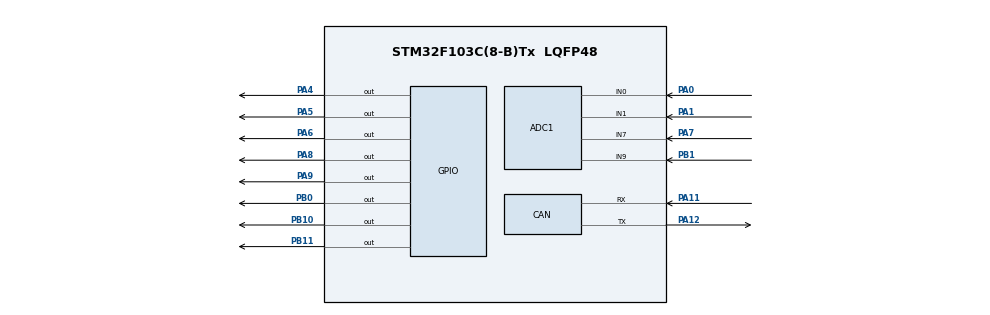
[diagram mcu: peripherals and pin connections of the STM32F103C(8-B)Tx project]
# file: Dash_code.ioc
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ADC1.Channel-0\#ChannelRegularConversion=ADC_CHANNEL_1
ADC1.NbrOfConversionFlag=1
ADC1.Rank-0\#ChannelRegularConversion=1
ADC1.SamplingTime-0\#ChannelRegularConversion=ADC_SAMPLETIME_1CYCLE_5
ADC1.master=1
CAN.CalculateTimeBit=6000
CAN.CalculateTimeQuantum=2000.0
Mcu.Family=STM32F1
Mcu.Name=STM32F103C(8-B)Tx
Mcu.Package=LQFP48
NVIC.PriorityGroup=NVIC_PRIORITYGROUP_4
PA0-WKUP.Signal=ADCx_IN0
PA1.Signal=ADCx_IN1
PA11.Mode=Master
PA11.Signal=CAN_RX
PA12.Mode=Master
PA12.Signal=CAN_TX
PA4.Signal=GPIO_Output
PA5.Signal=GPIO_Output
PA6.Signal=GPIO_Output
PA7.Signal=ADCx_IN7
PA8.Signal=GPIO_Output
PA9.Signal=GPIO_Output
PB0.Signal=GPIO_Output
PB1.Signal=ADCx_IN9
PB10.Signal=GPIO_Output
PB11.Signal=GPIO_Output
ProjectManager.HeapSize=0x200
ProjectManager.StackSize=0x400
ProjectManager.TargetToolchain=Makefile
RCC.APB1Freq_Value=8000000
RCC.APB2Freq_Value=8000000
SH.ADCx_IN0.0=ADC1_IN0,IN0
SH.ADCx_IN1.0=ADC1_IN1,IN1
SH.ADCx_IN7.0=ADC1_IN7,IN7
SH.ADCx_IN9.0=ADC1_IN9,IN9
VP_SYS_VS_ND.Mode=No_Debug
board=custom

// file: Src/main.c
/* USER CODE BEGIN Header */
/**
  ******************************************************************************
  * @file           : main.c
  * @brief          : Main program body
  ******************************************************************************
  ** This notice applies to any and all portions of this file
  * that are not between comment pairs USER CODE BEGIN and
  * USER CODE END. Other portions of this file, whether
  * inserted by the user or by software development tools
  * are owned by their respective copyright owners.
  *
  * COPYRIGHT(c) 2019 STMicroelectronics
  *
  * Redistribution and use in source and binary forms, with or without modification,
  * are permitted provided that the following conditions are met:
  *   1. Redistributions of source code must retain the above copyright notice,
  *      this list of conditions and the following disclaimer.
  *   2. Redistributions in binary form must reproduce the above copyright notice,
  *      this list of conditions and the following disclaimer in the documentation
  *      and/or other materials provided with the distribution.
  *   3. Neither the name of STMicroelectronics nor the names of its contributors
  *      may be used to endorse or promote products derived from this software
  *      without specific prior written permission.
  *
  * THIS SOFTWARE IS PROVIDED BY THE COPYRIGHT HOLDERS AND CONTRIBUTORS "AS IS"
  * AND ANY EXPRESS OR IMPLIED WARRANTIES, INCLUDING, BUT NOT LIMITED TO, THE
  * IMPLIED WARRANTIES OF MERCHANTABILITY AND FITNESS FOR A PARTICULAR PURPOSE ARE
  * DISCLAIMED. IN NO EVENT SHALL THE COPYRIGHT HOLDER OR CONTRIBUTORS BE LIABLE
  * FOR ANY DIRECT, INDIRECT, INCIDENTAL, SPECIAL, EXEMPLARY, OR CONSEQUENTIAL
  * DAMAGES (INCLUDING, BUT NOT LIMITED TO, PROCUREMENT OF SUBSTITUTE GOODS OR
  * SERVICES; LOSS OF USE, DATA, OR PROFITS; OR BUSINESS INTERRUPTION) HOWEVER
  * CAUSED AND ON ANY THEORY OF LIABILITY, WHETHER IN CONTRACT, STRICT LIABILITY,
  * OR TORT (INCLUDING NEGLIGENCE OR OTHERWISE) ARISING IN ANY WAY OUT OF THE USE
  * OF THIS SOFTWARE, EVEN IF ADVISED OF THE POSSIBILITY OF SUCH DAMAGE.
  *
  ******************************************************************************
  */
/* USER CODE END Header */

#include "main.h"

/* USER CODE BEGIN Includes */
//#include "stm32f0xx_hal.h"
/* USER CODE END Includes */

ADC_HandleTypeDef hadc1;
ADC_ChannelConfTypeDef sConfig;

CAN_HandleTypeDef hcan;

/* USER CODE BEGIN PV */
uint16_t adc0,adc1,adc7,adc9;

/* USER CODE END PV */

void SystemClock_Config(void);
static void MX_GPIO_Init(void);
static void MX_CAN_Init(void);
static void MX_ADC1_Init(void);
uint16_t readADC_Val(void);

int main(void)
{

  /* MCU Configuration--------------------------------------------------------*/

  /* Reset of all peripherals, Initializes the Flash interface and the Systick. */
  HAL_Init();

  /* Configure the system clock */
  SystemClock_Config();

  /* Initialize all configured peripherals */
  MX_GPIO_Init();
  MX_CAN_Init();
  MX_ADC1_Init();
  /* USER CODE BEGIN 2 */
  //ConfigureADC();
  HAL_ADC_Start_IT(&hadc1);
  sConfig.Channel = ADC_CHANNEL_0;
  adc0 = readADC_Val();
  sConfig.Channel = ADC_CHANNEL_1;
  adc1 = readADC_Val();
  sConfig.Channel = ADC_CHANNEL_7;
  adc7 = readADC_Val();
  sConfig.Channel = ADC_CHANNEL_9;
  adc9 = readADC_Val();
  /* USER CODE END 2 */

  /* Infinite loop */
  while (1)
  {

  }
}

uint16_t readADC_Val(void)
{
	//chConfig.Channel = channel; //configure channel to be read
	sConfig.Rank =  ADC_REGULAR_RANK_1;
	sConfig.SamplingTime = ADC_SAMPLETIME_1CYCLE_5;
	HAL_ADC_ConfigChannel(&hadc1, &sConfig);

	HAL_ADC_Start_IT(&hadc1);
	HAL_ADCEx_Calibration_Start(&hadc1);

	uint32_t value = HAL_ADC_GetValue(&hadc1);

	HAL_ADC_Stop_IT(&hadc1);
	sConfig.Rank = ADC_REGULAR_RANK_1;
	HAL_ADC_ConfigChannel(&hadc1,&sConfig);

	uint16_t value2 = (uint16_t)value;
	//sprintf(TextBuffer,"%u\n",value2);
	return value2;
}

void SystemClock_Config(void)
{
  RCC_OscInitTypeDef RCC_OscInitStruct = {0};
  RCC_ClkInitTypeDef RCC_ClkInitStruct = {0};
  RCC_PeriphCLKInitTypeDef PeriphClkInit = {0};

  /**Initializes the CPU, AHB and APB busses clocks
  */
  RCC_OscInitStruct.OscillatorType = RCC_OSCILLATORTYPE_HSI;
  RCC_OscInitStruct.HSIState = RCC_HSI_ON;
  RCC_OscInitStruct.HSICalibrationValue = RCC_HSICALIBRATION_DEFAULT;
  RCC_OscInitStruct.PLL.PLLState = RCC_PLL_NONE;
  if (HAL_RCC_OscConfig(&RCC_OscInitStruct) != HAL_OK)
  {
    Error_Handler();
  }
  /**Initializes the CPU, AHB and APB busses clocks
  */
  RCC_ClkInitStruct.ClockType = RCC_CLOCKTYPE_HCLK|RCC_CLOCKTYPE_SYSCLK
                              |RCC_CLOCKTYPE_PCLK1|RCC_CLOCKTYPE_PCLK2;
  RCC_ClkInitStruct.SYSCLKSource = RCC_SYSCLKSOURCE_HSI;
  RCC_ClkInitStruct.AHBCLKDivider = RCC_SYSCLK_DIV1;
  RCC_ClkInitStruct.APB1CLKDivider = RCC_HCLK_DIV1;
  RCC_ClkInitStruct.APB2CLKDivider = RCC_HCLK_DIV1;

  if (HAL_RCC_ClockConfig(&RCC_ClkInitStruct, FLASH_LATENCY_0) != HAL_OK)
  {
    Error_Handler();
  }
  PeriphClkInit.PeriphClockSelection = RCC_PERIPHCLK_ADC;
  PeriphClkInit.AdcClockSelection = RCC_ADCPCLK2_DIV2;
  if (HAL_RCCEx_PeriphCLKConfig(&PeriphClkInit) != HAL_OK)
  {
    Error_Handler();
  }
}

static void MX_ADC1_Init(void)
{

  //ADC_ChannelConfTypeDef sConfig = {0};

  /**Common config
  */
  hadc1.Instance = ADC1;
  hadc1.Init.ScanConvMode = ADC_SCAN_DISABLE;
  hadc1.Init.ContinuousConvMode = DISABLE;
  hadc1.Init.DiscontinuousConvMode = DISABLE;
  hadc1.Init.ExternalTrigConv = ADC_SOFTWARE_START;
  hadc1.Init.DataAlign = ADC_DATAALIGN_RIGHT;
  hadc1.Init.NbrOfConversion = 1;
  if (HAL_ADC_Init(&hadc1) != HAL_OK)
  {
    Error_Handler();
  }
  /**Configure Regular Channel
  */
  sConfig.Channel = ADC_CHANNEL_1;
  sConfig.Rank = ADC_REGULAR_RANK_1;
  sConfig.SamplingTime = ADC_SAMPLETIME_1CYCLE_5;
  if (HAL_ADC_ConfigChannel(&hadc1, &sConfig) != HAL_OK)
  {
    Error_Handler();
  }

}

static void MX_CAN_Init(void)
{

  hcan.Instance = CAN1;
  hcan.Init.Prescaler = 16;
  hcan.Init.Mode = CAN_MODE_NORMAL;
  hcan.Init.SyncJumpWidth = CAN_SJW_1TQ;
  hcan.Init.TimeSeg1 = CAN_BS1_1TQ;
  hcan.Init.TimeSeg2 = CAN_BS2_1TQ;
  hcan.Init.TimeTriggeredMode = DISABLE;
  hcan.Init.AutoBusOff = DISABLE;
  hcan.Init.AutoWakeUp = DISABLE;
  hcan.Init.AutoRetransmission = DISABLE;
  hcan.Init.ReceiveFifoLocked = DISABLE;
  hcan.Init.TransmitFifoPriority = DISABLE;
  if (HAL_CAN_Init(&hcan) != HAL_OK)
  {
    Error_Handler();
  }

}

static void MX_GPIO_Init(void)
{
  GPIO_InitTypeDef GPIO_InitStruct = {0};

  /* GPIO Ports Clock Enable */
  __HAL_RCC_GPIOA_CLK_ENABLE();
  __HAL_RCC_GPIOB_CLK_ENABLE();

  /*Configure GPIO pin Output Level */
  HAL_GPIO_WritePin(GPIOA, GPIO_PIN_4|GPIO_PIN_5|GPIO_PIN_6|GPIO_PIN_8
                          |GPIO_PIN_9, GPIO_PIN_RESET);

  /*Configure GPIO pin Output Level */
  HAL_GPIO_WritePin(GPIOB, GPIO_PIN_0|GPIO_PIN_10|GPIO_PIN_11, GPIO_PIN_RESET);

  /*Configure GPIO pins : PA4 PA5 PA6 PA8
                           PA9 */
  GPIO_InitStruct.Pin = GPIO_PIN_4|GPIO_PIN_5|GPIO_PIN_6|GPIO_PIN_8
                          |GPIO_PIN_9;
  GPIO_InitStruct.Mode = GPIO_MODE_OUTPUT_PP;
  GPIO_InitStruct.Pull = GPIO_NOPULL;
  GPIO_InitStruct.Speed = GPIO_SPEED_FREQ_LOW;
  HAL_GPIO_Init(GPIOA, &GPIO_InitStruct);

  /*Configure GPIO pins : PB0 PB10 PB11 */
  GPIO_InitStruct.Pin = GPIO_PIN_0|GPIO_PIN_10|GPIO_PIN_11;
  GPIO_InitStruct.Mode = GPIO_MODE_OUTPUT_PP;
  GPIO_InitStruct.Pull = GPIO_NOPULL;
  GPIO_InitStruct.Speed = GPIO_SPEED_FREQ_LOW;
  HAL_GPIO_Init(GPIOB, &GPIO_InitStruct);

}

void Error_Handler(void)
{
}

/************************ (C) COPYRIGHT STMicroelectronics *****END OF FILE****/
